# MCU_CTRL_MMR0_CFG0 register map
Vendor: Texas Instruments
Peripheral module from a debugger description file (folder am62P).
Registers are 32-bit, read-write, reset 0x0 unless marked. A register's access mark holds for its fields unless they carry their own. Offsets are as the file gives them; lines under a group give offsets from that group; [hi:lo] are bit positions; {n}, {i} and the like mark numbered series; 'fields as' and 'values as' point back to an identical list; <NAME> marks a mode.

## MCU_CTRL_MMR0_CFG0 (part 1 of 3)
0x1817C CFG0_RST_MAGIC_WORD
  [31:0] RST_MAGIC_WORD_MCU_MAGIC_WORD — A value of 0x00000000 (default value after reset) allows MAIN domain resets to also reset the MCU domain. Any other value allows reset propogation into the MCU domain to be blocked by ISO_CTRL.
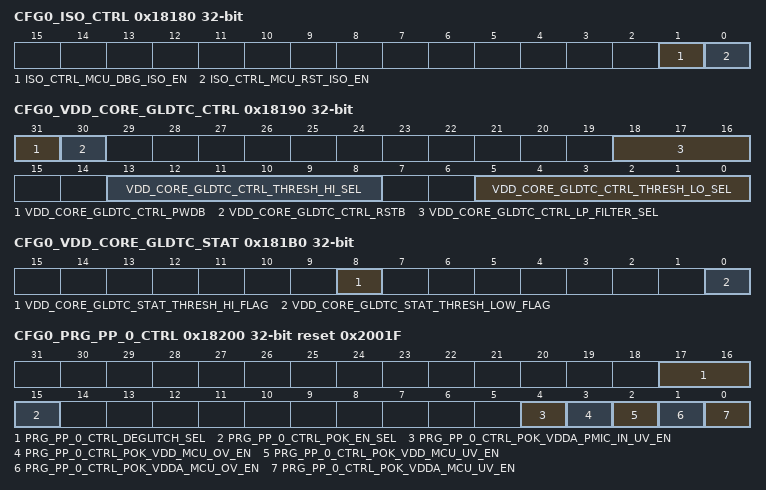
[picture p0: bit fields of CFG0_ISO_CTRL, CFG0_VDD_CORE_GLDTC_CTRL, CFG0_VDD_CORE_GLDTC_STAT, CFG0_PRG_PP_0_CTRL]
0x18180 CFG0_ISO_CTRL
  [1] ISO_CTRL_MCU_DBG_ISO_EN — Isolates the MCU domain from Debug. RST_MAGIC_WORD must also be non-zero for this bit to take effect. Field values (others are reserved): 1'b0 - DBG_ISO_OFF 1'b1 - DBG_ISO_ON
  [0] ISO_CTRL_MCU_RST_ISO_EN — Isolates the MCU domain from Warm Reset initiated by Main. RST_MAGIC_WORD must also be non-zero for this bit to take effect. Field values (others are reserved): 1'b0 - RST_ISO_OFF 1'b1 - RST_ISO_ON
0x18190 CFG0_VDD_CORE_GLDTC_CTRL
  [31] VDD_CORE_GLDTC_CTRL_PWDB — Power down - active low. Field values (others are reserved): 1'b0 - PWRDN 1'b1 - PWRUP
  [30] VDD_CORE_GLDTC_CTRL_RSTB — Reset - active low. To ensure proper operation, rstb must be not be de-asserted for at least 100 ns after power-up (pwdb de-asserted). Additionally, rstb must be toggled low at least 200 ns after any change in threshold or low-pass filter settings to prevent abnormal trigger events. Field values (others are reserved): 1'b0 - RESET 1'b1 - ACTIVE
  [18:16] VDD_CORE_GLDTC_CTRL_LP_FILTER_SEL — Selects the glitch detect low-pass filter bandwidth Field values (others are reserved): 3'b000 - BW_150KHz 3'b001 - BW_125KHz 3'b010 - BW_100KHz 3'b011 - BW_80KHz 3'b100 - BW_60KHz 3'b101 - BW_45KHz 3'b110 - BW_30KHz 3'b111 - BW_15KHz
  [13:8] VDD_CORE_GLDTC_CTRL_THRESH_HI_SEL — Selects the high voltage glitch threshold as a percentage of the monitored voltage Field values (others are reserved): 6'b000000 - PCT_VDD_93P5 6'b000001 - PCT_VDD_94 6'b000010 - PCT_VDD_94P5 6'b000011 - PCT_VDD_95 6'b000100 - PCT_VDD_95P5 6'b000101 - PCT_VDD_96 6'b000110 - PCT_VDD_96P5 6'b000111 - PCT_VDD_97 6'b001000 - PCT_VDD_97P5 6'b001001 - PCT_VDD_98 6'b001010 - PCT_VDD_98P5 6'b001011 - PCT_VDD_99 6'b001100 - PCT_VDD_99P5 6'b001101 - PCT_VDD_100 6'b001110 - PCT_VDD_100P5 6'b001111 - PCT_VDD_101 6'b010000 - PCT_VDD_101P5 6'b010001 - PCT_VDD_102 6'b010010 - PCT_VDD_102P5 6'b010011 - PCT_VDD_103 6'b010100 - PCT_VDD_103P5 6'b010101 - PCT_VDD_104 6'b010110 - PCT_VDD_104P5 6'b010111 - PCT_VDD_105 6'b011000 - PCT_VDD_105P5 6'b011001 - PCT_VDD_106 6'b011010 - PCT_VDD_106P5 6'b011011 - PCT_VDD_107 6'b011100 - PCT_VDD_107P5 6'b011101 - PCT_VDD_108 6'b011110 - PCT_VDD_108P5 6'b011111 - PCT_VDD_109 6'b100000 - PCT_VDD_109P5 6'b100001 - PCT_VDD_110 6'b100010 - PCT_VDD_111 6'b100011 - PCT_VDD_112 6'b100100 - PCT_VDD_113 6'b100101 - PCT_VDD_114 6'b100110 - PCT_VDD_115 6'b100111 - PCT_VDD_116 6'b101000 - PCT_VDD_117 6'b101001 - PCT_VDD_118 6'b101010 - PCT_VDD_119 6'b101011 - PCT_VDD_120 6'b101100 - PCT_VDD_121 6'b101101 - PCT_VDD_122 6'b101110 - PCT_VDD_123 6'b101111 - PCT_VDD_124 6'b110000 - PCT_VDD_125 6'b110001 - PCT_VDD_126 6'b110010 - PCT_VDD_127 6'b110011 - PCT_VDD_128 6'b110100 - PCT_VDD_129 6'b110101 - PCT_VDD_130 6'b110110 - PCT_VDD_131 6'b110111 - PCT_VDD_132 6'b111000 - PCT_VDD_133 6'b111001 - PCT_VDD_134 6'b111010 - PCT_VDD_135 6'b111011 - PCT_VDD_136 6'b111100 - PCT_VDD_137 6'b111101 - PCT_VDD_138 6'b111110 - PCT_VDD_139 6'b111111 - PCT_VDD_140
  [5:0] VDD_CORE_GLDTC_CTRL_THRESH_LO_SEL — Selects the low voltage glitch threshold as a percentage of the monitored voltage Field values (others are reserved): 6'b000000 - PCT_VDD_106P5 6'b000001 - PCT_VDD_106 6'b000010 - PCT_VDD_105P5 6'b000011 - PCT_VDD_105 6'b000100 - PCT_VDD_104P5 6'b000101 - PCT_VDD_104 6'b000110 - PCT_VDD_103P5 6'b000111 - PCT_VDD_103 6'b001000 - PCT_VDD_102P5 6'b001001 - PCT_VDD_102 6'b001010 - PCT_VDD_101P5 6'b001011 - PCT_VDD_101 6'b001100 - PCT_VDD_100P5 6'b001101 - PCT_VDD_100 6'b001110 - PCT_VDD_99P5 6'b001111 - PCT_VDD_99 6'b010000 - PCT_VDD_98P5 6'b010001 - PCT_VDD_98 6'b010010 - PCT_VDD_97P5 6'b010011 - PCT_VDD_97 6'b010100 - PCT_VDD_96P5 6'b010101 - PCT_VDD_96 6'b010110 - PCT_VDD_95P5 6'b010111 - PCT_VDD_95 6'b011000 - PCT_VDD_94P5 6'b011001 - PCT_VDD_94 6'b011010 - PCT_VDD_93P5 6'b011011 - PCT_VDD_93 6'b011100 - PCT_VDD_92P5 6'b011101 - PCT_VDD_92 6'b011110 - PCT_VDD_91P5 6'b011111 - PCT_VDD_91 6'b100000 - PCT_VDD_90P5 6'b100001 - PCT_VDD_90 6'b100010 - PCT_VDD_89 6'b100011 - PCT_VDD_88 6'b100100 - PCT_VDD_87 6'b100101 - PCT_VDD_86 6'b100110 - PCT_VDD_85 6'b100111 - PCT_VDD_84 6'b101000 - PCT_VDD_83 6'b101001 - PCT_VDD_82 6'b101010 - PCT_VDD_81 6'b101011 - PCT_VDD_80 6'b101100 - PCT_VDD_79 6'b101101 - PCT_VDD_78 6'b101110 - PCT_VDD_77 6'b101111 - PCT_VDD_76 6'b110000 - PCT_VDD_75 6'b110001 - PCT_VDD_74 6'b110010 - PCT_VDD_73 6'b110011 - PCT_VDD_72 6'b110100 - PCT_VDD_71 6'b110101 - PCT_VDD_70 6'b110110 - PCT_VDD_69 6'b110111 - PCT_VDD_68 6'b111000 - PCT_VDD_67 6'b111001 - PCT_VDD_66 6'b111010 - PCT_VDD_65 6'b111011 - PCT_VDD_64 6'b111100 - PCT_VDD_63 6'b111101 - PCT_VDD_62 6'b111110 - PCT_VDD_61 6'b111111 - PCT_VDD_60
0x181B0 CFG0_VDD_CORE_GLDTC_STAT ro
  [8] VDD_CORE_GLDTC_STAT_THRESH_HI_FLAG — High voltage flag. This flag is cleared by clearing the VDD_CORE_GLDTC_CTRL_rstb bit. Field values (others are reserved): 1'b0 - HV_UNKNOWN (not detected) 1'b1 - HV_DETECTED
  [0] VDD_CORE_GLDTC_STAT_THRESH_LOW_FLAG — Low voltage flag. This flag is cleared by clearing the VDD_CORE_GLDTC_CTRL_rstb bit. Field values (others are reserved): 1'b0 - LV_UNKNOWN (not detected) 1'b1 - LV_DETECTED
0x18200 CFG0_PRG_PP_0_CTRL reset 0x2001F
  [17:16] PRG_PP_0_CTRL_DEGLITCH_SEL — Deglitch period for PRG_PP1 POKs (microseconds) Field values (others are reserved): 2'b00 - DG_5_US 2'b01 - DG_10_US 2'b10 - DG_15_US 2'b11 - DG_20_US
  [15] PRG_PP_0_CTRL_POK_EN_SEL — Selects source of POK controls Field values (others are reserved): 1'b0 - TIEOFFS 1'b1 - PRG_PP0_CTRL_REG
  [4] PRG_PP_0_CTRL_POK_VDDA_PMIC_IN_UV_EN — Activate VDDA_PMIC_IN undervoltage POK detection Field values (others are reserved): 1'b0 - INACTIVE 1'b1 - ACTIVE
  [3] PRG_PP_0_CTRL_POK_VDD_MCU_OV_EN — Activate VDD_MCU overvoltage POK detection Field values (others are reserved): 1'b0 - INACTIVE 1'b1 - ACTIVE
  [2] PRG_PP_0_CTRL_POK_VDD_MCU_UV_EN — Activate VDD_MCU undervoltage POK detection Field values (others are reserved): 1'b0 - INACTIVE 1'b1 - ACTIVE
  [1] PRG_PP_0_CTRL_POK_VDDA_MCU_OV_EN — Activate 1.8V VDDA_MCU overvoltage POK detection Field values (others are reserved): 1'b0 - INACTIVE 1'b1 - ACTIVE
  [0] PRG_PP_0_CTRL_POK_VDDA_MCU_UV_EN — Activate 1.8V VDDA_MCU undervoltage POK detection Field values (others are reserved): 1'b0 - INACTIVE 1'b1 - ACTIVE
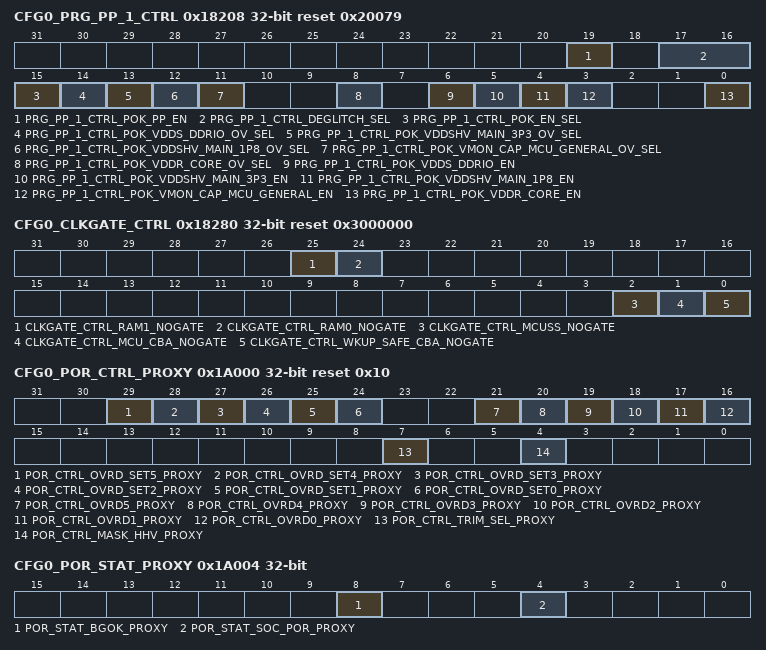
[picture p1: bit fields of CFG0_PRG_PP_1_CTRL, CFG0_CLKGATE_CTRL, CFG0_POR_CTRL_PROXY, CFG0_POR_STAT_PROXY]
0x18208 CFG0_PRG_PP_1_CTRL reset 0x20079
  [19] PRG_PP_1_CTRL_POK_PP_EN — POK ping-pong activate. When set, POKs with their ov_sel option set to UV_OR_PINGPONG are automatically cycled between UV and OV detection (ping-pong). POKs with ov_sel selecting OV are unaffected by this bit. Field values (others are reserved): 1'b0 - UV_FIXED 1'b1 - UV_PINGPONG_OV
  [17:16] PRG_PP_1_CTRL_DEGLITCH_SEL — Deglitch period for PRG_PP1 POKs (microseconds) Field values (others are reserved): 2'b00 - DG_5_US 2'b01 - DG_10_US 2'b10 - DG_15_US 2'b11 - DG_20_US
  [15] PRG_PP_1_CTRL_POK_EN_SEL — Selects source of POK controls Field values (others are reserved): 1'b0 - TIEOFFS 1'b1 - PRG_PP0_CTRL_REG
  [14] PRG_PP_1_CTRL_POK_VDDS_DDRIO_OV_SEL — POK_VDDS_DDRIO mode (undervoltage/ping-pong or over-voltage) Field values (others are reserved): 1'b0 - UV_OR_PINGPONG 1'b1 - OV
  [13] PRG_PP_1_CTRL_POK_VDDSHV_MAIN_3P3_OV_SEL — POK_VDDSHV_MAIN_3P3 mode (undervoltage/ping-pong or over-voltage) Field values (others are reserved): 1'b0 - UV_OR_PINGPONG 1'b1 - OV
  [12] PRG_PP_1_CTRL_POK_VDDSHV_MAIN_1P8_OV_SEL — POK_VDDSHV_MAIN_1P8 mode (undervoltage/ping-pong or over-voltage) Field values (others are reserved): 1'b0 - UV_OR_PINGPONG 1'b1 - OV
  [11] PRG_PP_1_CTRL_POK_VMON_CAP_MCU_GENERAL_OV_SEL — POK_VMON_CAP_MCU_GENERAL mode (undervoltage/ping-pong or over-voltage) Field values (others are reserved): 1'b0 - UV_OR_PINGPONG 1'b1 - OV
  [8] PRG_PP_1_CTRL_POK_VDDR_CORE_OV_SEL — POK_VDDR_CORE mode (undervoltage/ping-pong or over-voltage) Field values (others are reserved): 1'b0 - UV_OR_PINGPONG 1'b1 - OV
  [6] PRG_PP_1_CTRL_POK_VDDS_DDRIO_EN — Activate POK_VDDS_DDRIO (if pok_en_sel = 1): Field values (others are reserved): 1'b0 - INACTIVE 1'b1 - ACTIVE
  [5] PRG_PP_1_CTRL_POK_VDDSHV_MAIN_3P3_EN — Activate POK_VDDSHV_MAIN_3P3 (if pok_en_sel = 1): Field values (others are reserved): 1'b0 - INACTIVE 1'b1 - ACTIVE
  [4] PRG_PP_1_CTRL_POK_VDDSHV_MAIN_1P8_EN — Activate POK_VDDSHV_MAIN_1P8 (if pok_en_sel = 1): Field values (others are reserved): 1'b0 - INACTIVE 1'b1 - ACTIVE
  [3] PRG_PP_1_CTRL_POK_VMON_CAP_MCU_GENERAL_EN — Activate POK_VMON_CAP_MCU_GENERAL (if pok_en_sel = 1): Field values (others are reserved): 1'b0 - INACTIVE 1'b1 - ACTIVE
  [0] PRG_PP_1_CTRL_POK_VDDR_CORE_EN — Activate POK_VDDR_CORE (if pok_en_sel = 1): Field values (others are reserved): 1'b0 - INACTIVE 1'b1 - ACTIVE
0x18280 CFG0_CLKGATE_CTRL reset 0x3000000
  [25] CLKGATE_CTRL_RAM1_NOGATE — MCU SRAM1 auto clockgate on idle deactivate Field values (others are reserved): 1'b0 - INACTIVE 1'b1 - ACTIVE
  [24] CLKGATE_CTRL_RAM0_NOGATE — MCU SRAM1 auto clockgate on idle deactivate Field values (others are reserved): 1'b0 - INACTIVE 1'b1 - ACTIVE
  [2] CLKGATE_CTRL_MCUSS_NOGATE — MCU Subsystem auto clock gate on idle deactivate. Field values (others are reserved): 1'b0 - ACTIVE 1'b1 - INACTIVE
  [1] CLKGATE_CTRL_MCU_CBA_NOGATE — MCU domain Data CBASS auto clock gate on idle deactivate. Field values (others are reserved): 1'b0 - ACTIVE 1'b1 - INACTIVE
  [0] CLKGATE_CTRL_WKUP_SAFE_CBA_NOGATE — WKUP domain CBASS auto clock gate on idle deactivate. Field values (others are reserved): 1'b0 - ACTIVE 1'b1 - INACTIVE
0x19008 CFG0_LOCK6_KICK0
  [31:0] LOCK6_KICK0 — - KICK0 component
0x1900C CFG0_LOCK6_KICK1
  [31:0] LOCK6_KICK1 — - KICK1 component
{0x19100+4i} CFG0_CLAIMREG_P6_R{i}_READONLY ro (i=0..6)
  [31:0] CLAIMREG_P6_R{i}_READONLY — Claim bits for Partition 6
0x1A000 CFG0_POR_CTRL_PROXY reset 0x10
  [29] POR_CTRL_OVRD_SET5_PROXY — Override value when override is active, for RESERVED output. Field values (others are reserved): 1'b0 - OVERRIDE_TO_0 1'b1 - OVERRIDE_TO_1
  [28] POR_CTRL_OVRD_SET4_PROXY — Override value when override is active, for POKLVB output. Field values (others are reserved): 1'b0 - OVERRIDE_TO_0 1'b1 - OVERRIDE_TO_1
  [27] POR_CTRL_OVRD_SET3_PROXY — Override value when override is active, for POKLVA output. Field values (others are reserved): 1'b0 - OVERRIDE_TO_0 1'b1 - OVERRIDE_TO_1
  [26] POR_CTRL_OVRD_SET2_PROXY — Override value when override is active, for POKHV output. Field values (others are reserved): 1'b0 - OVERRIDE_TO_0 1'b1 - OVERRIDE_TO_1
  [25] POR_CTRL_OVRD_SET1_PROXY — Override value when override is active, for BGOK output. Field values (others are reserved): 1'b0 - OVERRIDE_TO_0 1'b1 - OVERRIDE_TO_1
  [24] POR_CTRL_OVRD_SET0_PROXY — Override value when override is active, for PORHV output. Field values (others are reserved): 1'b0 - OVERRIDE_TO_0 1'b1 - OVERRIDE_TO_1
  [21] POR_CTRL_OVRD5_PROXY — Activates override of RESERVED output Field values (others are reserved): 1'b0 - NORMAL_OPERATION 1'b1 - OVERRIDE_OUTPUT
  [20] POR_CTRL_OVRD4_PROXY — Activates override of POKLVB output Field values (others are reserved): 1'b0 - NORMAL_OPERATION 1'b1 - OVERRIDE_OUTPUT
  [19] POR_CTRL_OVRD3_PROXY — Activates override of POKLVA output Field values (others are reserved): 1'b0 - NORMAL_OPERATION 1'b1 - OVERRIDE_OUTPUT
  [18] POR_CTRL_OVRD2_PROXY — Activates override of POKHV output Field values (others are reserved): 1'b0 - NORMAL_OPERATION 1'b1 - OVERRIDE_OUTPUT
  [17] POR_CTRL_OVRD1_PROXY — Activates override of BGOK output Field values (others are reserved): 1'b0 - NORMAL_OPERATION 1'b1 - OVERRIDE_OUTPUT
  [16] POR_CTRL_OVRD0_PROXY — Activates override of PORHV output Field values (others are reserved): 1'b0 - NORMAL_OPERATION 1'b1 - OVERRIDE_OUTPUT
  [7] POR_CTRL_TRIM_SEL_PROXY — POR Trim Select - Fixed value or from POR_BANDGAP_CTRL and POR_POKxxx_CTRL registers MMRs Field values (others are reserved): 1'b0 - FIXED_TRIM 1'b1 - MMR_TRIM
  [4] POR_CTRL_MASK_HHV_PROXY — Mask HHV/SOC_PORz outputs when applying new trim values Field values (others are reserved): 1'b0 - UNMASK 1'b1 - MASK
0x1A004 CFG0_POR_STAT_PROXY ro
  [8] POR_STAT_BGOK_PROXY — Bandgap OK status Field values (others are reserved): 1'b0 - UNKNOWN 1'b1 - OK
  [4] POR_STAT_SOC_POR_PROXY — POR module status Field values (others are reserved): 1'b0 - POR_IS_ACTIVE 1'b1 - POR_IS_RESET
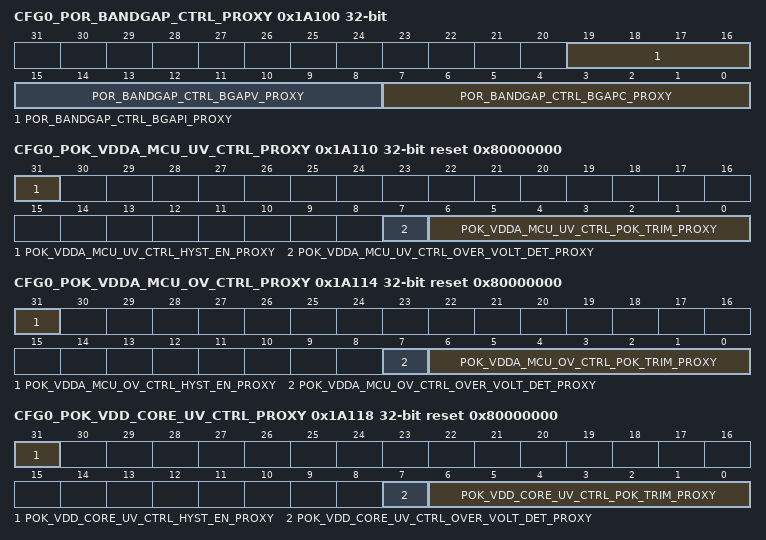
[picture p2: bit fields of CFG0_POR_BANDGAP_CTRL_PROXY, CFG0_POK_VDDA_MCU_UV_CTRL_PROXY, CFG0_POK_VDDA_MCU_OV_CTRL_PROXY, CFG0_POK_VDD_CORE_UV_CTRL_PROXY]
0x1A100 CFG0_POR_BANDGAP_CTRL_PROXY
  [19:16] POR_BANDGAP_CTRL_BGAPI_PROXY — Bandgap output current trim bits
  [15:8] POR_BANDGAP_CTRL_BGAPV_PROXY — Bandgap output voltage magnitude trim bits
  [7:0] POR_BANDGAP_CTRL_BGAPC_PROXY — Bandgap slope trim bits.
0x1A110 CFG0_POK_VDDA_MCU_UV_CTRL_PROXY reset 0x80000000
  [31] POK_VDDA_MCU_UV_CTRL_HYST_EN_PROXY — Activate POK hysteresis Field values (others are reserved): 1'b0 - INACTIVE 1'b1 - ACTIVE
  [7] POK_VDDA_MCU_UV_CTRL_OVER_VOLT_DET_PROXY — Over / under voltage detection mode Field values (others are reserved): 1'b0 - UNDERVOLTAGE_MODE 1'b1 - OVERVOLTAGE_MODE
  [6:0] POK_VDDA_MCU_UV_CTRL_POK_TRIM_PROXY — POK Trim Value from Fuse
0x1A114 CFG0_POK_VDDA_MCU_OV_CTRL_PROXY reset 0x80000000
  [31] POK_VDDA_MCU_OV_CTRL_HYST_EN_PROXY — Activate POK hysteresis Field values (others are reserved): 1'b0 - INACTIVE 1'b1 - ACTIVE
  [7] POK_VDDA_MCU_OV_CTRL_OVER_VOLT_DET_PROXY — Over / under voltage detection mode Field values (others are reserved): 1'b0 - UNDERVOLTAGE_MODE 1'b1 - OVERVOLTAGE_MODE
  [6:0] POK_VDDA_MCU_OV_CTRL_POK_TRIM_PROXY — POK Trim Value from Fuse
0x1A118 CFG0_POK_VDD_CORE_UV_CTRL_PROXY reset 0x80000000
  [31] POK_VDD_CORE_UV_CTRL_HYST_EN_PROXY — Activate POK hysteresis Field values (others are reserved): 1'b0 - INACTIVE 1'b1 - ACTIVE
  [7] POK_VDD_CORE_UV_CTRL_OVER_VOLT_DET_PROXY — Over / under voltage detection mode Field values (others are reserved): 1'b0 - UNDERVOLTAGE_MODE 1'b1 - OVERVOLTAGE_MODE
  [6:0] POK_VDD_CORE_UV_CTRL_POK_TRIM_PROXY — POK Trim Value from Fuse
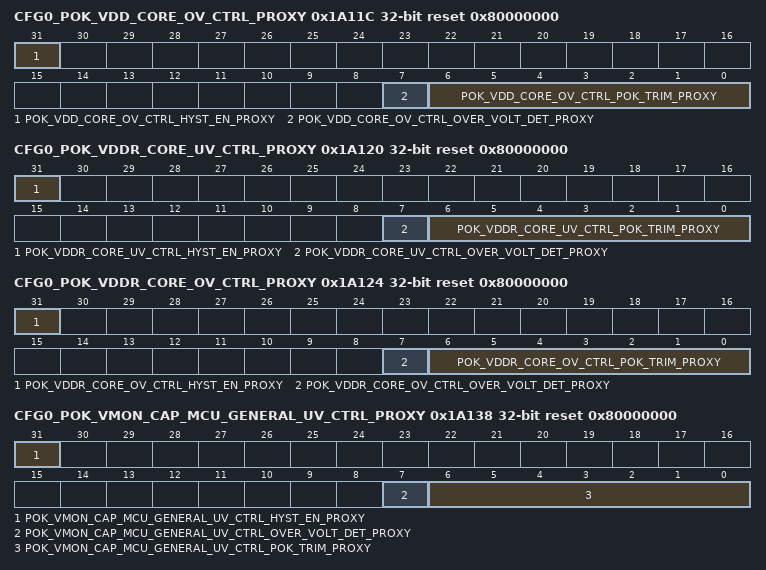
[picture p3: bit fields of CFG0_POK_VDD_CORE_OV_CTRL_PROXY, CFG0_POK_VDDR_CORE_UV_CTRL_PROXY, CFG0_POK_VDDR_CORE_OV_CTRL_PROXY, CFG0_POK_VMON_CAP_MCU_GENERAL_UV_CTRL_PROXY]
0x1A11C CFG0_POK_VDD_CORE_OV_CTRL_PROXY reset 0x80000000
  [31] POK_VDD_CORE_OV_CTRL_HYST_EN_PROXY — Activate POK hysteresis Field values (others are reserved): 1'b0 - INACTIVE 1'b1 - ACTIVE
  [7] POK_VDD_CORE_OV_CTRL_OVER_VOLT_DET_PROXY — Over / under voltage detection mode Field values (others are reserved): 1'b0 - UNDERVOLTAGE_MODE 1'b1 - OVERVOLTAGE_MODE
  [6:0] POK_VDD_CORE_OV_CTRL_POK_TRIM_PROXY — POK Trim Value from Fuse
0x1A120 CFG0_POK_VDDR_CORE_UV_CTRL_PROXY reset 0x80000000
  [31] POK_VDDR_CORE_UV_CTRL_HYST_EN_PROXY — Activate POK hysteresis Field values (others are reserved): 1'b0 - INACTIVE 1'b1 - ACTIVE
  [7] POK_VDDR_CORE_UV_CTRL_OVER_VOLT_DET_PROXY — Over / under voltage detection mode Field values (others are reserved): 1'b0 - UNDERVOLTAGE_MODE 1'b1 - OVERVOLTAGE_MODE
  [6:0] POK_VDDR_CORE_UV_CTRL_POK_TRIM_PROXY — POK Trim Value from Fuse
0x1A124 CFG0_POK_VDDR_CORE_OV_CTRL_PROXY reset 0x80000000
  [31] POK_VDDR_CORE_OV_CTRL_HYST_EN_PROXY — Activate POK hysteresis Field values (others are reserved): 1'b0 - INACTIVE 1'b1 - ACTIVE
  [7] POK_VDDR_CORE_OV_CTRL_OVER_VOLT_DET_PROXY — Over / under voltage detection mode Field values (others are reserved): 1'b0 - UNDERVOLTAGE_MODE 1'b1 - OVERVOLTAGE_MODE
  [6:0] POK_VDDR_CORE_OV_CTRL_POK_TRIM_PROXY — POK Trim Value from Fuse
0x1A138 CFG0_POK_VMON_CAP_MCU_GENERAL_UV_CTRL_PROXY reset 0x80000000
  [31] POK_VMON_CAP_MCU_GENERAL_UV_CTRL_HYST_EN_PROXY — Activate POK hysteresis Field values (others are reserved): 1'b0 - INACTIVE 1'b1 - ACTIVE
  [7] POK_VMON_CAP_MCU_GENERAL_UV_CTRL_OVER_VOLT_DET_PROXY — Over / under voltage detection mode Field values (others are reserved): 1'b0 - UNDERVOLTAGE_MODE 1'b1 - OVERVOLTAGE_MODE
  [6:0] POK_VMON_CAP_MCU_GENERAL_UV_CTRL_POK_TRIM_PROXY — POK Trim Value from Fuse
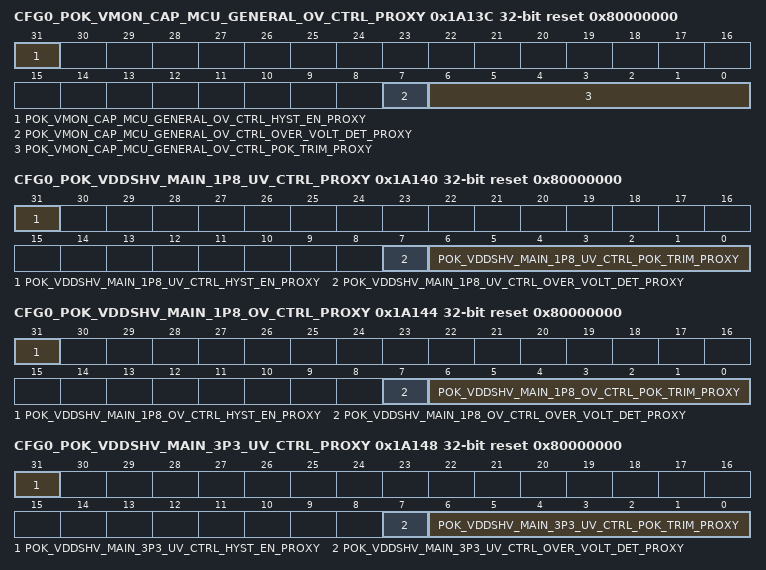
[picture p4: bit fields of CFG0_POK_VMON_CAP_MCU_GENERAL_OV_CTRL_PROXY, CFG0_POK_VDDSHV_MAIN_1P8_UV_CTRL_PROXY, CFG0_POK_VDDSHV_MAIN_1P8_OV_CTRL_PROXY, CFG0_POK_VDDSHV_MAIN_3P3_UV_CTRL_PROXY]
0x1A13C CFG0_POK_VMON_CAP_MCU_GENERAL_OV_CTRL_PROXY reset 0x80000000
  [31] POK_VMON_CAP_MCU_GENERAL_OV_CTRL_HYST_EN_PROXY — Activate POK hysteresis Field values (others are reserved): 1'b0 - INACTIVE 1'b1 - ACTIVE
  [7] POK_VMON_CAP_MCU_GENERAL_OV_CTRL_OVER_VOLT_DET_PROXY — Over / under voltage detection mode Field values (others are reserved): 1'b0 - UNDERVOLTAGE_MODE 1'b1 - OVERVOLTAGE_MODE
  [6:0] POK_VMON_CAP_MCU_GENERAL_OV_CTRL_POK_TRIM_PROXY — POK Trim Value from Fuse
0x1A140 CFG0_POK_VDDSHV_MAIN_1P8_UV_CTRL_PROXY reset 0x80000000
  [31] POK_VDDSHV_MAIN_1P8_UV_CTRL_HYST_EN_PROXY — Activate POK hysteresis Field values (others are reserved): 1'b0 - INACTIVE 1'b1 - ACTIVE
  [7] POK_VDDSHV_MAIN_1P8_UV_CTRL_OVER_VOLT_DET_PROXY — Over / under voltage detection mode Field values (others are reserved): 1'b0 - UNDERVOLTAGE_MODE 1'b1 - OVERVOLTAGE_MODE
  [6:0] POK_VDDSHV_MAIN_1P8_UV_CTRL_POK_TRIM_PROXY — POK Trim Value from Fuse
0x1A144 CFG0_POK_VDDSHV_MAIN_1P8_OV_CTRL_PROXY reset 0x80000000
  [31] POK_VDDSHV_MAIN_1P8_OV_CTRL_HYST_EN_PROXY — Activate POK hysteresis Field values (others are reserved): 1'b0 - INACTIVE 1'b1 - ACTIVE
  [7] POK_VDDSHV_MAIN_1P8_OV_CTRL_OVER_VOLT_DET_PROXY — Over / under voltage detection mode Field values (others are reserved): 1'b0 - UNDERVOLTAGE_MODE 1'b1 - OVERVOLTAGE_MODE
  [6:0] POK_VDDSHV_MAIN_1P8_OV_CTRL_POK_TRIM_PROXY — POK Trim Value from Fuse
0x1A148 CFG0_POK_VDDSHV_MAIN_3P3_UV_CTRL_PROXY reset 0x80000000
  [31] POK_VDDSHV_MAIN_3P3_UV_CTRL_HYST_EN_PROXY — Activate POK hysteresis Field values (others are reserved): 1'b0 - INACTIVE 1'b1 - ACTIVE
  [7] POK_VDDSHV_MAIN_3P3_UV_CTRL_OVER_VOLT_DET_PROXY — Over / under voltage detection mode Field values (others are reserved): 1'b0 - UNDERVOLTAGE_MODE 1'b1 - OVERVOLTAGE_MODE
  [6:0] POK_VDDSHV_MAIN_3P3_UV_CTRL_POK_TRIM_PROXY — POK Trim Value from Fuse
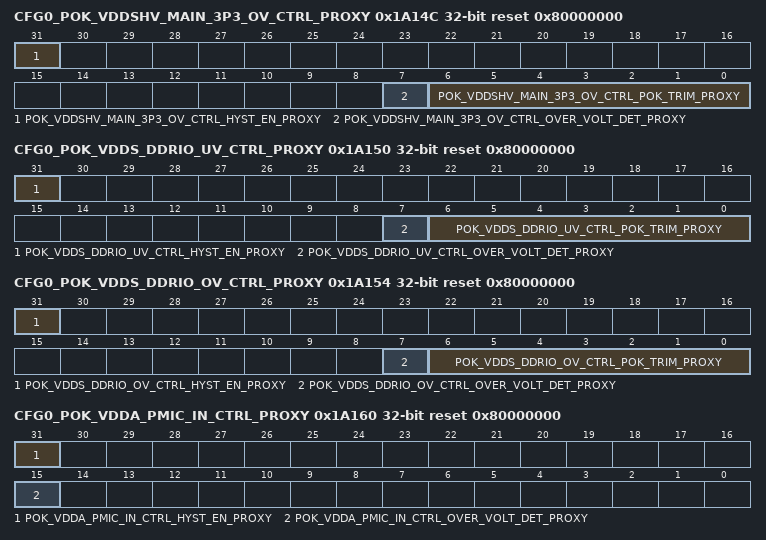
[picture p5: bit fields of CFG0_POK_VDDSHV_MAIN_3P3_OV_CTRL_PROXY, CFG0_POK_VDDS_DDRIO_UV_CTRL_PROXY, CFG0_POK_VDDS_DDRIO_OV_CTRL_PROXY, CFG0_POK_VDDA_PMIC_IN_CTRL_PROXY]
0x1A14C CFG0_POK_VDDSHV_MAIN_3P3_OV_CTRL_PROXY reset 0x80000000
  [31] POK_VDDSHV_MAIN_3P3_OV_CTRL_HYST_EN_PROXY — Activate POK hysteresis Field values (others are reserved): 1'b0 - INACTIVE 1'b1 - ACTIVE
  [7] POK_VDDSHV_MAIN_3P3_OV_CTRL_OVER_VOLT_DET_PROXY — Over / under voltage detection mode Field values (others are reserved): 1'b0 - UNDERVOLTAGE_MODE 1'b1 - OVERVOLTAGE_MODE
  [6:0] POK_VDDSHV_MAIN_3P3_OV_CTRL_POK_TRIM_PROXY — POK Trim Value from Fuse
0x1A150 CFG0_POK_VDDS_DDRIO_UV_CTRL_PROXY reset 0x80000000
  [31] POK_VDDS_DDRIO_UV_CTRL_HYST_EN_PROXY — Activate POK hysteresis Field values (others are reserved): 1'b0 - INACTIVE 1'b1 - ACTIVE
  [7] POK_VDDS_DDRIO_UV_CTRL_OVER_VOLT_DET_PROXY — Over / under voltage detection mode Field values (others are reserved): 1'b0 - UNDERVOLTAGE_MODE 1'b1 - OVERVOLTAGE_MODE
  [6:0] POK_VDDS_DDRIO_UV_CTRL_POK_TRIM_PROXY — POK Trim Value from Fuse
0x1A154 CFG0_POK_VDDS_DDRIO_OV_CTRL_PROXY reset 0x80000000
  [31] POK_VDDS_DDRIO_OV_CTRL_HYST_EN_PROXY — Activate POK hysteresis Field values (others are reserved): 1'b0 - INACTIVE 1'b1 - ACTIVE
  [7] POK_VDDS_DDRIO_OV_CTRL_OVER_VOLT_DET_PROXY — Over / under voltage detection mode Field values (others are reserved): 1'b0 - UNDERVOLTAGE_MODE 1'b1 - OVERVOLTAGE_MODE
  [6:0] POK_VDDS_DDRIO_OV_CTRL_POK_TRIM_PROXY — POK Trim Value from Fuse
0x1A160 CFG0_POK_VDDA_PMIC_IN_CTRL_PROXY reset 0x80000000
  [31] POK_VDDA_PMIC_IN_CTRL_HYST_EN_PROXY — Activate POK hysteresis Field values (others are reserved): 1'b0 - INACTIVE 1'b1 - ACTIVE
  [15] POK_VDDA_PMIC_IN_CTRL_OVER_VOLT_DET_PROXY — Over / under voltage detection mode Field values (others are reserved): 1'b0 - UNDERVOLTAGE_MODE 1'b1 - OVERVOLTAGE_MODE
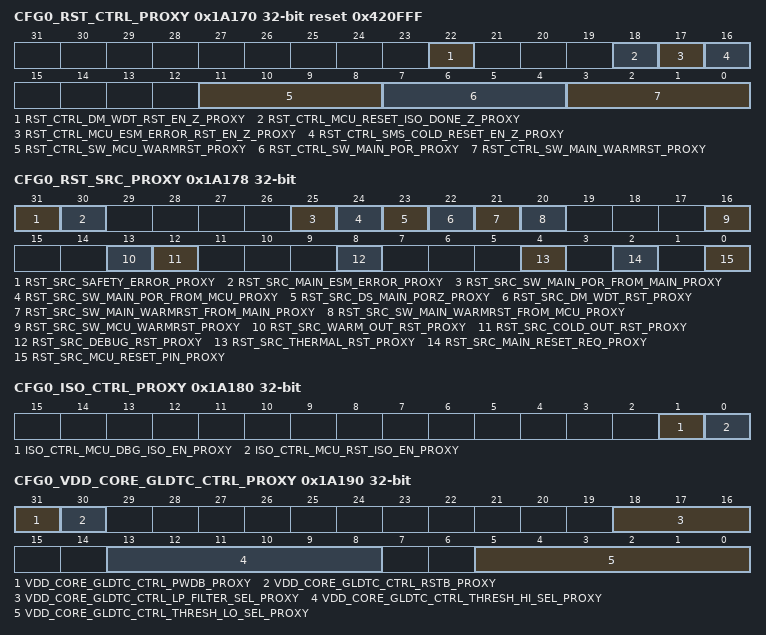
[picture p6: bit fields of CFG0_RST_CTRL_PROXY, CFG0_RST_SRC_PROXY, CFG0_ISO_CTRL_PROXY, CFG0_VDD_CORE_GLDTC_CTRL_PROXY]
0x1A170 CFG0_RST_CTRL_PROXY reset 0x420FFF
  [22] RST_CTRL_DM_WDT_RST_EN_Z_PROXY — Block Reset from DM WDT propogating to MCU domain Field values (others are reserved): 1'b0 - PROPOGATE 1'b1 - BLOCK
  [18] RST_CTRL_MCU_RESET_ISO_DONE_Z_PROXY — Block Main Domain Warm Reset MCU domain Field values (others are reserved): 1'b0 - PROPOGATE 1'b1 - BLOCK
  [17] RST_CTRL_MCU_ESM_ERROR_RST_EN_Z_PROXY — Block Reset of MCU by ESM Field values (others are reserved): 1'b0 - PROPOGATE 1'b1 - BLOCK
  [16] RST_CTRL_SMS_COLD_RESET_EN_Z_PROXY — Block Reset of MCU by SMS Field values (others are reserved): 1'b0 - PROPOGATE 1'b1 - BLOCK
  [11:8] RST_CTRL_SW_MCU_WARMRST_PROXY — Causes MAIN Domain Warm Reset. This is a fault tolerant bitfield. Automatically resets to 4'b1111 after write. Field values (others are reserved): 4'b0110 - FORCE_RESET 4'b1111 - INACTIVE
  [7:4] RST_CTRL_SW_MAIN_POR_PROXY — Causes MAIN Domain Power On Reset. This is a fault tolerant bitfield. Automatically resets to 4'b1111 after write. Field values (others are reserved): 4'b0110 - FORCE_RESET 4'b1111 - INACTIVE
  [3:0] RST_CTRL_SW_MAIN_WARMRST_PROXY — Causes MAIN Domain Warm Reset. This is a fault tolerant bitfield. Automatically resets to 4'b1111 after write. Field values (others are reserved): 4'b0110 - FORCE_RESET 4'b1111 - INACTIVE
0x1A174 CFG0_RST_STAT_PROXY ro
  [0] RST_STAT_MAIN_RESETSTATZ_PROXY — Status of Main Domain Reset: Field values (others are reserved): 1'b0 - BLOCKED 1'b1 - PROPOGATE
0x1A178 CFG0_RST_SRC_PROXY access not given
  [31] RST_SRC_SAFETY_ERROR_PROXY — Reset Caused by MCU ESM Error. Write 1 to Clear. Field values (others are reserved): 1'b0 - UNKNOWN 1'b1 - DETECTED (access R/W1TC)
  [30] RST_SRC_MAIN_ESM_ERROR_PROXY — Reset Caused by Main ESM Error. Write 1 to Clear. Field values (others are reserved): 1'b0 - UNKNOWN 1'b1 - DETECTED (access R/W1TC)
  [25] RST_SRC_SW_MAIN_POR_FROM_MAIN_PROXY — Software Main Power On Reset From CTRL_MMR0. Write 1 to Clear. Field values (others are reserved): 1'b0 - UNKNOWN 1'b1 - DETECTED (access R/W1TC)
  [24] RST_SRC_SW_MAIN_POR_FROM_MCU_PROXY — Software Main Power On Reset From MCU_CTRL_MMR0. Write 1 to Clear. Field values (others are reserved): 1'b0 - UNKNOWN 1'b1 - DETECTED (access R/W1TC)
  [23] RST_SRC_DS_MAIN_PORZ_PROXY — Reset of Main/Wkup Domains while in Deep Sleep, as a result of an MCU Warm Reset. Write 1 to Clear. Field values (others are reserved): 1'b0 - UNKNOWN 1'b1 - DETECTED (access R/W1TC)
  [22] RST_SRC_DM_WDT_RST_PROXY — Watchdog Initiated Reset. Write 1 to Clear. Field values (others are reserved): 1'b0 - UNKNOWN 1'b1 - DETECTED (access R/W1TC)
  [21] RST_SRC_SW_MAIN_WARMRST_FROM_MAIN_PROXY — Software Main Warm Reset From CTRL_MMR0. Write 1 to Clear. Field values (others are reserved): 1'b0 - UNKNOWN 1'b1 - DETECTED (access R/W1TC)
  [20] RST_SRC_SW_MAIN_WARMRST_FROM_MCU_PROXY — Software Main Warm Reset From MCU_CTRL_MMR0. Write 1 to Clear. Field values (others are reserved): 1'b0 - UNKNOWN 1'b1 - DETECTED (access R/W1TC)
  [16] RST_SRC_SW_MCU_WARMRST_PROXY — Software Warm Reset. Write 1 to Clear. Field values (others are reserved): 1'b0 - UNKNOWN 1'b1 - DETECTED (access R/W1TC)
  [13] RST_SRC_WARM_OUT_RST_PROXY — SMS Warm Reset. Write 1 to Clear. Field values (others are reserved): 1'b0 - UNKNOWN 1'b1 - DETECTED (access R/W1TC)
  [12] RST_SRC_COLD_OUT_RST_PROXY — SMS Cold Reset. Write 1 to Clear. Field values (others are reserved): 1'b0 - UNKNOWN 1'b1 - DETECTED (access R/W1TC)
  [8] RST_SRC_DEBUG_RST_PROXY — Debug Subsystem Initiated Reset. Write 1 to Clear. Field values (others are reserved): 1'b0 - UNKNOWN 1'b1 - DETECTED (access R/W1TC)
  [4] RST_SRC_THERMAL_RST_PROXY — Thermal Reset. Write 1 to Clear. Field values (others are reserved): 1'b0 - UNKNOWN 1'b1 - DETECTED (access R/W1TC)
  [2] RST_SRC_MAIN_RESET_REQ_PROXY — Main Reset Pin. Write 1 to Clear. Field values (others are reserved): 1'b0 - UNKNOWN 1'b1 - DETECTED (access R/W1TC)
  [0] RST_SRC_MCU_RESET_PIN_PROXY — Rest Caused by MCU Reset Pin. Write 1 to Clear. Field values (others are reserved): 1'b0 - UNKNOWN 1'b1 - DETECTED (access R/W1TC)
0x1A17C CFG0_RST_MAGIC_WORD_PROXY
  [31:0] RST_MAGIC_WORD_MCU_MAGIC_WORD_PROXY — A value of 0x00000000 (default value after reset) allows MAIN domain resets to also reset the MCU domain. Any other value allows reset propogation into the MCU domain to be blocked by ISO_CTRL.
0x1A180 CFG0_ISO_CTRL_PROXY
  [1] ISO_CTRL_MCU_DBG_ISO_EN_PROXY — Isolates the MCU domain from Debug. RST_MAGIC_WORD must also be non-zero for this bit to take effect. Field values (others are reserved): 1'b0 - DBG_ISO_OFF 1'b1 - DBG_ISO_ON
  [0] ISO_CTRL_MCU_RST_ISO_EN_PROXY — Isolates the MCU domain from Warm Reset initiated by Main. RST_MAGIC_WORD must also be non-zero for this bit to take effect. Field values (others are reserved): 1'b0 - RST_ISO_OFF 1'b1 - RST_ISO_ON
0x1A190 CFG0_VDD_CORE_GLDTC_CTRL_PROXY
  [31] VDD_CORE_GLDTC_CTRL_PWDB_PROXY — Power down - active low. Field values (others are reserved): 1'b0 - PWRDN 1'b1 - PWRUP
  [30] VDD_CORE_GLDTC_CTRL_RSTB_PROXY — Reset - active low. To ensure proper operation, rstb must be not be de-asserted for at least 100 ns after power-up (pwdb de-asserted). Additionally, rstb must be toggled low at least 200 ns after any change in threshold or low-pass filter settings to prevent abnormal trigger events. Field values (others are reserved): 1'b0 - RESET 1'b1 - ACTIVE
  [18:16] VDD_CORE_GLDTC_CTRL_LP_FILTER_SEL_PROXY — Selects the glitch detect low-pass filter bandwidth Field values (others are reserved): 3'b000 - BW_150KHz 3'b001 - BW_125KHz 3'b010 - BW_100KHz 3'b011 - BW_80KHz 3'b100 - BW_60KHz 3'b101 - BW_45KHz 3'b110 - BW_30KHz 3'b111 - BW_15KHz
  [13:8] VDD_CORE_GLDTC_CTRL_THRESH_HI_SEL_PROXY — Selects the high voltage glitch threshold as a percentage of the monitored voltage Field values (others are reserved): 6'b000000 - PCT_VDD_93P5 6'b000001 - PCT_VDD_94 6'b000010 - PCT_VDD_94P5 6'b000011 - PCT_VDD_95 6'b000100 - PCT_VDD_95P5 6'b000101 - PCT_VDD_96 6'b000110 - PCT_VDD_96P5 6'b000111 - PCT_VDD_97 6'b001000 - PCT_VDD_97P5 6'b001001 - PCT_VDD_98 6'b001010 - PCT_VDD_98P5 6'b001011 - PCT_VDD_99 6'b001100 - PCT_VDD_99P5 6'b001101 - PCT_VDD_100 6'b001110 - PCT_VDD_100P5 6'b001111 - PCT_VDD_101 6'b010000 - PCT_VDD_101P5 6'b010001 - PCT_VDD_102 6'b010010 - PCT_VDD_102P5 6'b010011 - PCT_VDD_103 6'b010100 - PCT_VDD_103P5 6'b010101 - PCT_VDD_104 6'b010110 - PCT_VDD_104P5 6'b010111 - PCT_VDD_105 6'b011000 - PCT_VDD_105P5 6'b011001 - PCT_VDD_106 6'b011010 - PCT_VDD_106P5 6'b011011 - PCT_VDD_107 6'b011100 - PCT_VDD_107P5 6'b011101 - PCT_VDD_108 6'b011110 - PCT_VDD_108P5 6'b011111 - PCT_VDD_109 6'b100000 - PCT_VDD_109P5 6'b100001 - PCT_VDD_110 6'b100010 - PCT_VDD_111 6'b100011 - PCT_VDD_112 6'b100100 - PCT_VDD_113 6'b100101 - PCT_VDD_114 6'b100110 - PCT_VDD_115 6'b100111 - PCT_VDD_116 6'b101000 - PCT_VDD_117 6'b101001 - PCT_VDD_118 6'b101010 - PCT_VDD_119 6'b101011 - PCT_VDD_120 6'b101100 - PCT_VDD_121 6'b101101 - PCT_VDD_122 6'b101110 - PCT_VDD_123 6'b101111 - PCT_VDD_124 6'b110000 - PCT_VDD_125 6'b110001 - PCT_VDD_126 6'b110010 - PCT_VDD_127 6'b110011 - PCT_VDD_128 6'b110100 - PCT_VDD_129 6'b110101 - PCT_VDD_130 6'b110110 - PCT_VDD_131 6'b110111 - PCT_VDD_132 6'b111000 - PCT_VDD_133 6'b111001 - PCT_VDD_134 6'b111010 - PCT_VDD_135 6'b111011 - PCT_VDD_136 6'b111100 - PCT_VDD_137 6'b111101 - PCT_VDD_138 6'b111110 - PCT_VDD_139 6'b111111 - PCT_VDD_140
  [5:0] VDD_CORE_GLDTC_CTRL_THRESH_LO_SEL_PROXY — Selects the low voltage glitch threshold as a percentage of the monitored voltage Field values (others are reserved): 6'b000000 - PCT_VDD_106P5 6'b000001 - PCT_VDD_106 6'b000010 - PCT_VDD_105P5 6'b000011 - PCT_VDD_105 6'b000100 - PCT_VDD_104P5 6'b000101 - PCT_VDD_104 6'b000110 - PCT_VDD_103P5 6'b000111 - PCT_VDD_103 6'b001000 - PCT_VDD_102P5 6'b001001 - PCT_VDD_102 6'b001010 - PCT_VDD_101P5 6'b001011 - PCT_VDD_101 6'b001100 - PCT_VDD_100P5 6'b001101 - PCT_VDD_100 6'b001110 - PCT_VDD_99P5 6'b001111 - PCT_VDD_99 6'b010000 - PCT_VDD_98P5 6'b010001 - PCT_VDD_98 6'b010010 - PCT_VDD_97P5 6'b010011 - PCT_VDD_97 6'b010100 - PCT_VDD_96P5 6'b010101 - PCT_VDD_96 6'b010110 - PCT_VDD_95P5 6'b010111 - PCT_VDD_95 6'b011000 - PCT_VDD_94P5 6'b011001 - PCT_VDD_94 6'b011010 - PCT_VDD_93P5 6'b011011 - PCT_VDD_93 6'b011100 - PCT_VDD_92P5 6'b011101 - PCT_VDD_92 6'b011110 - PCT_VDD_91P5 6'b011111 - PCT_VDD_91 6'b100000 - PCT_VDD_90P5 6'b100001 - PCT_VDD_90 6'b100010 - PCT_VDD_89 6'b100011 - PCT_VDD_88 6'b100100 - PCT_VDD_87 6'b100101 - PCT_VDD_86 6'b100110 - PCT_VDD_85 6'b100111 - PCT_VDD_84 6'b101000 - PCT_VDD_83 6'b101001 - PCT_VDD_82 6'b101010 - PCT_VDD_81 6'b101011 - PCT_VDD_80 6'b101100 - PCT_VDD_79 6'b101101 - PCT_VDD_78 6'b101110 - PCT_VDD_77 6'b101111 - PCT_VDD_76 6'b110000 - PCT_VDD_75 6'b110001 - PCT_VDD_74 6'b110010 - PCT_VDD_73 6'b110011 - PCT_VDD_72 6'b110100 - PCT_VDD_71 6'b110101 - PCT_VDD_70 6'b110110 - PCT_VDD_69 6'b110111 - PCT_VDD_68 6'b111000 - PCT_VDD_67 6'b111001 - PCT_VDD_66 6'b111010 - PCT_VDD_65 6'b111011 - PCT_VDD_64 6'b111100 - PCT_VDD_63 6'b111101 - PCT_VDD_62 6'b111110 - PCT_VDD_61 6'b111111 - PCT_VDD_60
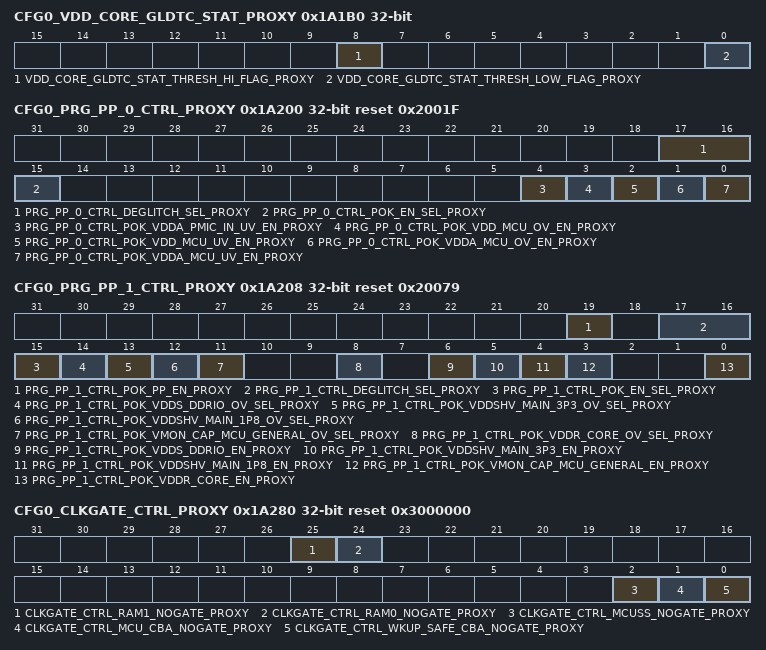
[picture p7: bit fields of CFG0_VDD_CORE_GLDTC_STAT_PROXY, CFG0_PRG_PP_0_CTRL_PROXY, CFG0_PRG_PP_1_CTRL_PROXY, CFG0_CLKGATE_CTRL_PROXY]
0x1A1B0 CFG0_VDD_CORE_GLDTC_STAT_PROXY ro
  [8] VDD_CORE_GLDTC_STAT_THRESH_HI_FLAG_PROXY — High voltage flag. This flag is cleared by clearing the VDD_CORE_GLDTC_CTRL_rstb bit. Field values (others are reserved): 1'b0 - HV_UNKNOWN (not detected) 1'b1 - HV_DETECTED
  [0] VDD_CORE_GLDTC_STAT_THRESH_LOW_FLAG_PROXY — Low voltage flag. This flag is cleared by clearing the VDD_CORE_GLDTC_CTRL_rstb bit. Field values (others are reserved): 1'b0 - LV_UNKNOWN (not detected) 1'b1 - LV_DETECTED
0x1A200 CFG0_PRG_PP_0_CTRL_PROXY reset 0x2001F
  [17:16] PRG_PP_0_CTRL_DEGLITCH_SEL_PROXY — Deglitch period for PRG_PP1 POKs (microseconds) Field values (others are reserved): 2'b00 - DG_5_US 2'b01 - DG_10_US 2'b10 - DG_15_US 2'b11 - DG_20_US
  [15] PRG_PP_0_CTRL_POK_EN_SEL_PROXY — Selects source of POK controls Field values (others are reserved): 1'b0 - TIEOFFS 1'b1 - PRG_PP0_CTRL_REG
  [4] PRG_PP_0_CTRL_POK_VDDA_PMIC_IN_UV_EN_PROXY — Activate VDDA_PMIC_IN undervoltage POK detection Field values (others are reserved): 1'b0 - INACTIVE 1'b1 - ACTIVE
  [3] PRG_PP_0_CTRL_POK_VDD_MCU_OV_EN_PROXY — Activate VDD_MCU overvoltage POK detection Field values (others are reserved): 1'b0 - INACTIVE 1'b1 - ACTIVE
  [2] PRG_PP_0_CTRL_POK_VDD_MCU_UV_EN_PROXY — Activate VDD_MCU undervoltage POK detection Field values (others are reserved): 1'b0 - INACTIVE 1'b1 - ACTIVE
  [1] PRG_PP_0_CTRL_POK_VDDA_MCU_OV_EN_PROXY — Activate 1.8V VDDA_MCU overvoltage POK detection Field values (others are reserved): 1'b0 - INACTIVE 1'b1 - ACTIVE
  [0] PRG_PP_0_CTRL_POK_VDDA_MCU_UV_EN_PROXY — Activate 1.8V VDDA_MCU undervoltage POK detection Field values (others are reserved): 1'b0 - INACTIVE 1'b1 - ACTIVE
0x1A208 CFG0_PRG_PP_1_CTRL_PROXY reset 0x20079
  [19] PRG_PP_1_CTRL_POK_PP_EN_PROXY — POK ping-pong activate. When set, POKs with their ov_sel option set to UV_OR_PINGPONG are automatically cycled between UV and OV detection (ping-pong). POKs with ov_sel selecting OV are unaffected by this bit. Field values (others are reserved): 1'b0 - UV_FIXED 1'b1 - UV_PINGPONG_OV
  [17:16] PRG_PP_1_CTRL_DEGLITCH_SEL_PROXY — Deglitch period for PRG_PP1 POKs (microseconds) Field values (others are reserved): 2'b00 - DG_5_US 2'b01 - DG_10_US 2'b10 - DG_15_US 2'b11 - DG_20_US
  [15] PRG_PP_1_CTRL_POK_EN_SEL_PROXY — Selects source of POK controls Field values (others are reserved): 1'b0 - TIEOFFS 1'b1 - PRG_PP0_CTRL_REG
  [14] PRG_PP_1_CTRL_POK_VDDS_DDRIO_OV_SEL_PROXY — POK_VDDS_DDRIO mode (undervoltage/ping-pong or over-voltage) Field values (others are reserved): 1'b0 - UV_OR_PINGPONG 1'b1 - OV
  [13] PRG_PP_1_CTRL_POK_VDDSHV_MAIN_3P3_OV_SEL_PROXY — POK_VDDSHV_MAIN_3P3 mode (undervoltage/ping-pong or over-voltage) Field values (others are reserved): 1'b0 - UV_OR_PINGPONG 1'b1 - OV
  [12] PRG_PP_1_CTRL_POK_VDDSHV_MAIN_1P8_OV_SEL_PROXY — POK_VDDSHV_MAIN_1P8 mode (undervoltage/ping-pong or over-voltage) Field values (others are reserved): 1'b0 - UV_OR_PINGPONG 1'b1 - OV
  [11] PRG_PP_1_CTRL_POK_VMON_CAP_MCU_GENERAL_OV_SEL_PROXY — POK_VMON_CAP_MCU_GENERAL mode (undervoltage/ping-pong or over-voltage) Field values (others are reserved): 1'b0 - UV_OR_PINGPONG 1'b1 - OV
  [8] PRG_PP_1_CTRL_POK_VDDR_CORE_OV_SEL_PROXY — POK_VDDR_CORE mode (undervoltage/ping-pong or over-voltage) Field values (others are reserved): 1'b0 - UV_OR_PINGPONG 1'b1 - OV
  [6] PRG_PP_1_CTRL_POK_VDDS_DDRIO_EN_PROXY — Activate POK_VDDS_DDRIO (if pok_en_sel = 1): Field values (others are reserved): 1'b0 - INACTIVE 1'b1 - ACTIVE
  [5] PRG_PP_1_CTRL_POK_VDDSHV_MAIN_3P3_EN_PROXY — Activate POK_VDDSHV_MAIN_3P3 (if pok_en_sel = 1): Field values (others are reserved): 1'b0 - INACTIVE 1'b1 - ACTIVE
  [4] PRG_PP_1_CTRL_POK_VDDSHV_MAIN_1P8_EN_PROXY — Activate POK_VDDSHV_MAIN_1P8 (if pok_en_sel = 1): Field values (others are reserved): 1'b0 - INACTIVE 1'b1 - ACTIVE
  [3] PRG_PP_1_CTRL_POK_VMON_CAP_MCU_GENERAL_EN_PROXY — Activate POK_VMON_CAP_MCU_GENERAL (if pok_en_sel = 1): Field values (others are reserved): 1'b0 - INACTIVE 1'b1 - ACTIVE
  [0] PRG_PP_1_CTRL_POK_VDDR_CORE_EN_PROXY — Activate POK_VDDR_CORE (if pok_en_sel = 1): Field values (others are reserved): 1'b0 - INACTIVE 1'b1 - ACTIVE
0x1A280 CFG0_CLKGATE_CTRL_PROXY reset 0x3000000
  [25] CLKGATE_CTRL_RAM1_NOGATE_PROXY — MCU SRAM1 auto clockgate on idle deactivate Field values (others are reserved): 1'b0 - INACTIVE 1'b1 - ACTIVE
  [24] CLKGATE_CTRL_RAM0_NOGATE_PROXY — MCU SRAM1 auto clockgate on idle deactivate Field values (others are reserved): 1'b0 - INACTIVE 1'b1 - ACTIVE
  [2] CLKGATE_CTRL_MCUSS_NOGATE_PROXY — MCU Subsystem auto clock gate on idle deactivate. Field values (others are reserved): 1'b0 - ACTIVE 1'b1 - INACTIVE
  [1] CLKGATE_CTRL_MCU_CBA_NOGATE_PROXY — MCU domain Data CBASS auto clock gate on idle deactivate. Field values (others are reserved): 1'b0 - ACTIVE 1'b1 - INACTIVE
  [0] CLKGATE_CTRL_WKUP_SAFE_CBA_NOGATE_PROXY — WKUP domain CBASS auto clock gate on idle deactivate. Field values (others are reserved): 1'b0 - ACTIVE 1'b1 - INACTIVE
0x1B008 CFG0_LOCK6_KICK0_PROXY
  [31:0] LOCK6_KICK0_PROXY — - KICK0 component
0x1B00C CFG0_LOCK6_KICK1_PROXY
  [31:0] LOCK6_KICK1_PROXY — - KICK1 component
{0x1B100+4i} CFG0_CLAIMREG_P6_R{i} (i=0..6)
  [31:0] CLAIMREG_P6_R{i} — Claim bits for Partition 6
